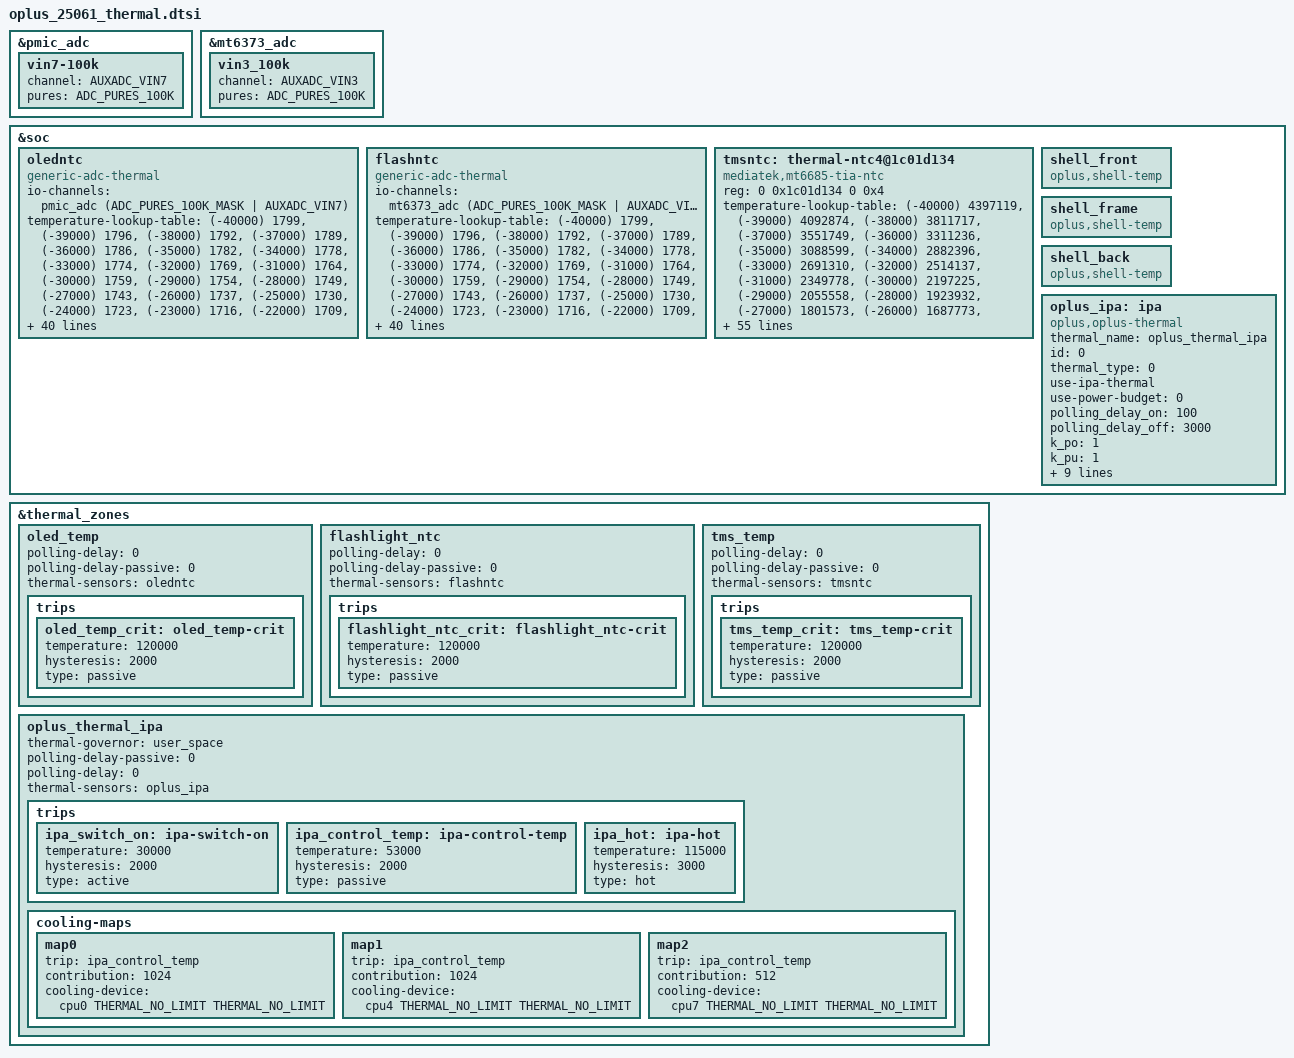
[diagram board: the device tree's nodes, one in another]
// SPDX-License-Identifier: GPL-2.0
/* Copyright (c) 2025 MediaTek Inc. */
#include <dt-bindings/clock/mt6991-clk.h>
#include <dt-bindings/thermal/thermal.h>

&pmic_adc {
	vin7-100k {
		channel = <AUXADC_VIN7>;
		pures = <ADC_PURES_100K>;
	};
};

&mt6373_adc {
	vin3_100k {
		channel = <AUXADC_VIN3>;
		pures = <ADC_PURES_100K>;
	};
};

&soc {
	oledntc: oledntc {
		compatible = "generic-adc-thermal";
		#thermal-sensor-cells = <0>;
		io-channels = <&pmic_adc (ADC_PURES_100K_MASK | AUXADC_VIN7)>;
		io-channel-names = "sensor-channel";
		temperature-lookup-table =
			<(-40000) 1799>,
			<(-39000) 1796>,
			<(-38000) 1792>,
			<(-37000) 1789>,
			<(-36000) 1786>,
			<(-35000) 1782>,
			<(-34000) 1778>,
			<(-33000) 1774>,
			<(-32000) 1769>,
			<(-31000) 1764>,
			<(-30000) 1759>,
			<(-29000) 1754>,
			<(-28000) 1749>,
			<(-27000) 1743>,
			<(-26000) 1737>,
			<(-25000) 1730>,
			<(-24000) 1723>,
			<(-23000) 1716>,
			<(-22000) 1709>,
			<(-21000) 1701>,
			<(-20000) 1692>,
			<(-19000) 1684>,
			<(-18000) 1675>,
			<(-17000) 1665>,
			<(-16000) 1655>,
			<(-15000) 1645>,
			<(-14000) 1634>,
			<(-13000) 1623>,
			<(-12000) 1612>,
			<(-11000) 1600>,
			<(-10000) 1587>,
			<(-9000) 1574>,
			<(-8000) 1561>,
			<(-7000) 1547>,
			<(-6000) 1532>,
			<(-5000) 1518>,
			<(-4000) 1502>,
			<(-3000) 1487>,
			<(-2000) 1471>,
			<(-1000) 1454>,
			<0 1437>,
			<1000 1419>,
			<2000 1402>,
			<3000 1383>,
			<4000 1365>,
			<5000 1346>,
			<6000 1326>,
			<7000 1306>,
			<8000 1286>,
			<9000 1266>,
			<10000 1245>,
			<11000 1225>,
			<12000 1203>,
			<13000 1182>,
			<14000 1161>,
			<15000 1139>,
			<16000 1117>,
			<17000 1095>,
			<18000 1073>,
			<19000 1051>,
			<20000 1029>,
			<21000 1007>,
			<22000 985>,
			<23000 963>,
			<24000 941>,
			<25000 920>,
			<26000 898>,
			<27000 876>,
			<28000 855>,
			<29000 834>,
			<30000 813>,
			<31000 792>,
			<32000 772>,
			<33000 751>,
			<34000 731>,
			<35000 712>,
			<36000 692>,
			<37000 673>,
			<38000 655>,
			<39000 636>,
			<40000 618>,
			<41000 601>,
			<42000 583>,
			<43000 566>,
			<44000 550>,
			<45000 534>,
			<46000 518>,
			<47000 502>,
			<48000 487>,
			<49000 472>,
			<50000 458>,
			<51000 444>,
			<52000 430>,
			<53000 417>,
			<54000 404>,
			<55000 392>,
			<56000 380>,
			<57000 368>,
			<58000 356>,
			<59000 345>,
			<60000 334>,
			<61000 324>,
			<62000 313>,
			<63000 303>,
			<64000 294>,
			<65000 284>,
			<66000 275>,
			<67000 267>,
			<68000 258>,
			<69000 250>,
			<70000 242>,
			<71000 234>,
			<72000 227>,
			<73000 220>,
			<74000 213>,
			<75000 206>,
			<76000 199>,
			<77000 193>,
			<78000 187>,
			<79000 181>,
			<80000 175>,
			<81000 170>,
			<82000 164>,
			<83000 159>,
			<84000 154>,
			<85000 149>,
			<86000 145>,
			<87000 140>,
			<88000 136>,
			<89000 132>,
			<90000 128>,
			<91000 124>,
			<92000 120>,
			<93000 116>,
			<94000 113>,
			<95000 109>,
			<96000 106>,
			<97000 103>,
			<98000 99>,
			<99000 96>,
			<100000 94>,
			<101000 91>,
			<102000 88>,
			<103000 85>,
			<104000 83>,
			<105000 80>,
			<106000 78>,
			<107000 76>,
			<108000 73>,
			<109000 71>,
			<110000 69>,
			<111000 67>,
			<112000 65>,
			<113000 63>,
			<114000 61>,
			<115000 60>,
			<116000 58>,
			<117000 56>,
			<118000 55>,
			<119000 53>,
			<120000 52>,
			<121000 50>,
			<122000 49>,
			<123000 47>,
			<124000 46>,
			<125000 45>;
	};

	flashntc: flashntc {
		compatible = "generic-adc-thermal";
		#thermal-sensor-cells = <0>;
		io-channels = <&mt6373_adc (ADC_PURES_100K_MASK | AUXADC_VIN3)>;
		io-channel-names = "sensor-channel";
		temperature-lookup-table =
			<(-40000) 1799>,
			<(-39000) 1796>,
			<(-38000) 1792>,
			<(-37000) 1789>,
			<(-36000) 1786>,
			<(-35000) 1782>,
			<(-34000) 1778>,
			<(-33000) 1774>,
			<(-32000) 1769>,
			<(-31000) 1764>,
			<(-30000) 1759>,
			<(-29000) 1754>,
			<(-28000) 1749>,
			<(-27000) 1743>,
			<(-26000) 1737>,
			<(-25000) 1730>,
			<(-24000) 1723>,
			<(-23000) 1716>,
			<(-22000) 1709>,
			<(-21000) 1701>,
			<(-20000) 1692>,
			<(-19000) 1684>,
			<(-18000) 1675>,
			<(-17000) 1665>,
			<(-16000) 1655>,
			<(-15000) 1645>,
			<(-14000) 1634>,
			<(-13000) 1623>,
			<(-12000) 1612>,
			<(-11000) 1600>,
			<(-10000) 1587>,
			<(-9000) 1574>,
			<(-8000) 1561>,
			<(-7000) 1547>,
			<(-6000) 1532>,
			<(-5000) 1518>,
			<(-4000) 1502>,
			<(-3000) 1487>,
			<(-2000) 1471>,
			<(-1000) 1454>,
			<0 1437>,
			<1000 1419>,
			<2000 1402>,
			<3000 1383>,
			<4000 1365>,
			<5000 1346>,
			<6000 1326>,
			<7000 1306>,
			<8000 1286>,
			<9000 1266>,
			<10000 1245>,
			<11000 1225>,
			<12000 1203>,
			<13000 1182>,
			<14000 1161>,
			<15000 1139>,
			<16000 1117>,
			<17000 1095>,
			<18000 1073>,
			<19000 1051>,
			<20000 1029>,
			<21000 1007>,
			<22000 985>,
			<23000 963>,
			<24000 941>,
			<25000 920>,
			<26000 898>,
			<27000 876>,
			<28000 855>,
			<29000 834>,
			<30000 813>,
			<31000 792>,
			<32000 772>,
			<33000 751>,
			<34000 731>,
			<35000 712>,
			<36000 692>,
			<37000 673>,
			<38000 655>,
			<39000 636>,
			<40000 618>,
			<41000 601>,
			<42000 583>,
			<43000 566>,
			<44000 550>,
			<45000 534>,
			<46000 518>,
			<47000 502>,
			<48000 487>,
			<49000 472>,
			<50000 458>,
			<51000 444>,
			<52000 430>,
			<53000 417>,
			<54000 404>,
			<55000 392>,
			<56000 380>,
			<57000 368>,
			<58000 356>,
			<59000 345>,
			<60000 334>,
			<61000 324>,
			<62000 313>,
			<63000 303>,
			<64000 294>,
			<65000 284>,
			<66000 275>,
			<67000 267>,
			<68000 258>,
			<69000 250>,
			<70000 242>,
			<71000 234>,
			<72000 227>,
			<73000 220>,
			<74000 213>,
			<75000 206>,
			<76000 199>,
			<77000 193>,
			<78000 187>,
			<79000 181>,
			<80000 175>,
			<81000 170>,
			<82000 164>,
			<83000 159>,
			<84000 154>,
			<85000 149>,
			<86000 145>,
			<87000 140>,
			<88000 136>,
			<89000 132>,
			<90000 128>,
			<91000 124>,
			<92000 120>,
			<93000 116>,
			<94000 113>,
			<95000 109>,
			<96000 106>,
			<97000 103>,
			<98000 99>,
			<99000 96>,
			<100000 94>,
			<101000 91>,
			<102000 88>,
			<103000 85>,
			<104000 83>,
			<105000 80>,
			<106000 78>,
			<107000 76>,
			<108000 73>,
			<109000 71>,
			<110000 69>,
			<111000 67>,
			<112000 65>,
			<113000 63>,
			<114000 61>,
			<115000 60>,
			<116000 58>,
			<117000 56>,
			<118000 55>,
			<119000 53>,
			<120000 52>,
			<121000 50>,
			<122000 49>,
			<123000 47>,
			<124000 46>,
			<125000 45>;
	};

	tmsntc: thermal-ntc4@1c01d134 {
		compatible = "mediatek,mt6685-tia-ntc";
		#thermal-sensor-cells = <0>;
		reg = <0 0x1c01d134 0 0x4>; /* TIA DATA T3 */
		temperature-lookup-table =
			<(-40000) 4397119>,
			<(-39000) 4092874>,
			<(-38000) 3811717>,
			<(-37000) 3551749>,
			<(-36000) 3311236>,
			<(-35000) 3088599>,
			<(-34000) 2882396>,
			<(-33000) 2691310>,
			<(-32000) 2514137>,
			<(-31000) 2349778>,
			<(-30000) 2197225>,
			<(-29000) 2055558>,
			<(-28000) 1923932>,
			<(-27000) 1801573>,
			<(-26000) 1687773>,
			<(-25000) 1581881>,
			<(-24000) 1483100>,
			<(-23000) 1391113>,
			<(-22000) 1305413>,
			<(-21000) 1225531>,
			<(-20000) 1151037>,
			<(-19000) 1081535>,
			<(-18000) 1016661>,
			<(-17000) 956080>,
			<(-16000) 899481>,
			<(-15000) 846579>,
			<(-14000) 797111>,
			<(-13000) 750834>,
			<(-12000) 707524>,
			<(-11000) 666972>,
			<(-10000) 628988>,
			<(-9000) 593342>,
			<(-8000) 559931>,
			<(-7000) 528602>,
			<(-6000) 499212>,
			<(-5000) 471632>,
			<(-4000) 445772>,
			<(-3000) 421480>,
			<(-2000) 398652>,
			<(-1000) 377193>,
			<0 357012>,
			<1000 338006>,
			<2000 320122>,
			<3000 303287>,
			<4000 287434>,
			<5000 272500>,
			<6000 258426>,
			<7000 245160>,
			<8000 232649>,
			<9000 220847>,
			<10000 209710>,
			<11000 199196>,
			<12000 189268>,
			<13000 179890>,
			<14000 171027>,
			<15000 162651>,
			<16000 154726>,
			<17000 147232>,
			<18000 140142>,
			<19000 133432>,
			<20000 127080>,
			<21000 121066>,
			<22000 115368>,
			<23000 109970>,
			<24000 104852>,
			<25000 100000>,
			<26000 95398>,
			<27000 91032>,
			<28000 86889>,
			<29000 82956>,
			<30000 79222>,
			<31000 75675>,
			<32000 72306>,
			<33000 69104>,
			<34000 66061>,
			<35000 63167>,
			<36000 60415>,
			<37000 57797>,
			<38000 55306>,
			<39000 52934>,
			<40000 50677>,
			<41000 48528>,
			<42000 46482>,
			<43000 44533>,
			<44000 42675>,
			<45000 40904>,
			<46000 39213>,
			<47000 37601>,
			<48000 36063>,
			<49000 34595>,
			<50000 33195>,
			<51000 31859>,
			<52000 30584>,
			<53000 29366>,
			<54000 28203>,
			<55000 27091>,
			<56000 26028>,
			<57000 25013>,
			<58000 24042>,
			<59000 23113>,
			<60000 22224>,
			<61000 21374>,
			<62000 20560>,
			<63000 19782>,
			<64000 19036>,
			<65000 18322>,
			<66000 17640>,
			<67000 16986>,
			<68000 16360>,
			<69000 15759>,
			<70000 15184>,
			<71000 14631>,
			<72000 14100>,
			<73000 13591>,
			<74000 13103>,
			<75000 12635>,
			<76000 12187>,
			<77000 11756>,
			<78000 11343>,
			<79000 10946>,
			<80000 10565>,
			<81000 10199>,
			<82000 9847>,
			<83000 9509>,
			<84000 9184>,
			<85000 8872>,
			<86000 8572>,
			<87000 8283>,
			<88000 8005>,
			<89000 7738>,
			<90000 7481>,
			<91000 7234>,
			<92000 6997>,
			<93000 6769>,
			<94000 6548>,
			<95000 6337>,
			<96000 6132>,
			<97000 5934>,
			<98000 5744>,
			<99000 5561>,
			<100000 5384>,
			<101000 5214>,
			<102000 5051>,
			<103000 4893>,
			<104000 4741>,
			<105000 4594>,
			<106000 4453>,
			<107000 4316>,
			<108000 4184>,
			<109000 4057>,
			<110000 3934>,
			<111000 3816>,
			<112000 3701>,
			<113000 3591>,
			<114000 3484>,
			<115000 3380>,
			<116000 3281>,
			<117000 3185>,
			<118000 3093>,
			<119000 3003>,
			<120000 2916>,
			<121000 2832>,
			<122000 2751>,
			<123000 2672>,
			<124000 2596>,
			<125000 2522>;
	};

	//#ifdef OPLUS_FEATURE_POWER_THERMAL
	shell_front {
		compatible = "oplus,shell-temp";
	};
	shell_frame {
		compatible = "oplus,shell-temp";
	};
	shell_back {
		compatible = "oplus,shell-temp";
	};
	//#endif /* OPLUS_FEATURE_POWER_THERMAL */

	//#ifdef CONFIG_OPLUS_IPA
	oplus_ipa: ipa {
		compatible = "oplus,oplus-thermal";
		thermal_name = "oplus_thermal_ipa";
		id = <0>;
		thermal_type = <0>;
		#thermal-sensor-cells = <0>;
		use-ipa-thermal;
		use-power-budget = <0>;
		polling_delay_on = <100>;
		polling_delay_off = <3000>;
		k_po = <1>;
		k_pu = <1>;
		k_i = <1>;
		k_d = <0>;
		i_max = <2>;
		integral_cutoff = <10>;
		sustainable_power = <9999>;
		thermal_work_affinity = "0-8";
		cdev_min_power = <466 329 272 0 0 0>;
		use-thermalcontrol-limit = <1>;
		clt_state_limit = <0 0 0 0 0 0>;
	};
	//#endif /* CONFIG_OPLUS_IPA */
};

&thermal_zones {
	oled_temp: oled_temp {
		polling-delay = <0>; /* milliseconds */
		polling-delay-passive = <0>; /* milliseconds */
		thermal-sensors = <&oledntc>;
		trips {
			oled_temp_crit: oled_temp-crit {
				temperature = <120000>;
				hysteresis = <2000>;
				type = "passive";
			};
		};
	};

	flashlight_ntc: flashlight_ntc {
		polling-delay = <0>; /* milliseconds */
		polling-delay-passive = <0>; /* milliseconds */
		thermal-sensors = <&flashntc>;
		trips {
			flashlight_ntc_crit: flashlight_ntc-crit {
				temperature = <120000>;
				hysteresis = <2000>;
				type = "passive";
			};
		};
	};

	tms_temp: tms_temp {
		polling-delay = <0>; /* milliseconds */
		polling-delay-passive = <0>; /* milliseconds */
		thermal-sensors = <&tmsntc>;
		trips {
			tms_temp_crit: tms_temp-crit {
				temperature = <120000>;
				hysteresis = <2000>;
				type = "passive";
			};
		};
	};

	oplus_thermal_ipa {
		thermal-governor = "user_space";
		polling-delay-passive = <0>;
		polling-delay = <0>;
		thermal-sensors = <&oplus_ipa>;
		trips {
			ipa_switch_on: ipa-switch-on {
				temperature = <30000>;
				hysteresis = <2000>;
				type = "active";
			};
			ipa_control_temp: ipa-control-temp {
				temperature = <53000>;
				hysteresis = <2000>;
				type = "passive";
			};
			ipa_hot: ipa-hot {
				temperature = <115000>;
				hysteresis = <3000>;
				type = "hot";
			};
		};
		cooling-maps {
			map0 {
				trip = <&ipa_control_temp>;
				contribution = <1024>;
				cooling-device = <&cpu0 THERMAL_NO_LIMIT THERMAL_NO_LIMIT>;
				#cooling-cells = <2>;
			};
			map1 {
				trip = <&ipa_control_temp>;
				contribution = <1024>;
				cooling-device = <&cpu4 THERMAL_NO_LIMIT THERMAL_NO_LIMIT>;
				#cooling-cells = <2>;
			};
			map2 {
				trip = <&ipa_control_temp>;
				contribution = <512>;
				cooling-device = <&cpu7 THERMAL_NO_LIMIT THERMAL_NO_LIMIT>;
				#cooling-cells = <2>;
			};
		};
	};
};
